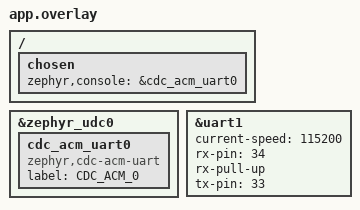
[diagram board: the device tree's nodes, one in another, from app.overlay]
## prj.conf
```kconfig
CONFIG_STDOUT_CONSOLE=y

# Heap and stacks
CONFIG_HEAP_MEM_POOL_SIZE=16384
CONFIG_MAIN_STACK_SIZE=8192
CONFIG_SYSTEM_WORKQUEUE_STACK_SIZE=4096

CONFIG_LOG=n
CONFIG_USE_SEGGER_RTT=y
CONFIG_LOG_BACKEND_RTT=y
CONFIG_LOG_BACKEND_RTT_MODE_DROP=y
#CONFIG_LOG_MODE_IMMEDIATE=y

# CONFIG_DEBUG_OPTIMIZATIONS=y
CONFIG_NEWLIB_LIBC=y
CONFIG_NEWLIB_LIBC_FLOAT_PRINTF=y
CONFIG_I2C=y

# USB
CONFIG_USB_DEVICE_STACK=y
CONFIG_USB_DEVICE_MANUFACTURER="Nordic Semiconductor"
CONFIG_USB_DEVICE_PRODUCT="nRF52840DK"
CONFIG_USB_COMPOSITE_DEVICE=y
CONFIG_USB_CDC_ACM=y
CONFIG_USB_CDC_ACM_RINGBUF_SIZE=4096

# Uart Config
CONFIG_NRFX_UARTE0=y
CONFIG_UART_ASYNC_API=y
```

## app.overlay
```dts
/*
 * Copyright (c) 2021 Nordic Semiconductor ASA
 *
 * SPDX-License-Identifier: Apache-2.0
 */

/ {
    chosen {
        zephyr,console = &cdc_acm_uart0;
    };
};

&zephyr_udc0 {
    cdc_acm_uart0: cdc_acm_uart0 {
        compatible = "zephyr,cdc-acm-uart";
        label = "CDC_ACM_0";
    };
};

&uart1 {
    status = "okay";
    current-speed = <115200>;
    rx-pin = <34>;
    rx-pull-up;
    tx-pin = <33>;
};
```

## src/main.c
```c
/*
 * Copyright (c) 2019 Infineon Technologies AG
 *
 * SPDX-License-Identifier: Apache-2.0
 */

#include <zephyr.h>
#include <device.h>

#include <drivers/sensor.h>
#include <stdlib.h>
#include <stdio.h>
#include <uart_communication.h>
#include <dps368.h>
#include <scheduling.h>
#include <parse_and_send.h>
#include <logging/log.h>

LOG_MODULE_REGISTER(app, LOG_LEVEL_INF);

void main(void)
{
    LOG_INF("Hello DPS368\n");
    uart_init();
    dps368_init();
    workqueue_init_and_start();
    transaction_nr = 1;

    LOG_INF("dev %p name %s\n", data.i2c_master, data.i2c_master->name);

    while (1) 
    {
        send_tmp_and_psr_value_to_oem();
        k_sleep(K_MSEC(1000));
    }
}
```
